# LPC13xx register map
File version: 1
CPU: 
Registers are 32-bit, read-write, reset 0x0 unless marked. A register's access mark holds for its fields unless they carry their own. Offsets are from the block's base; [hi:lo] are bit positions; {n}, {i} and the like mark numbered series; 'fields as' and 'values as' point back to an identical list.

## SYSCON — Product name title=UM10375 Chapter title=LPC13xx System configuration Modification date=4/4/2011 Major revision=2 Minor revision=2
Base 0x40048000
0x00 SYSMEMREMAP reset 0x2 — System memory remap
  [1:0] MAP
    0=BOOT_LOADER_MODE_IN (Boot Loader Mode. Interrupt vectors are re-mapped to Boot ROM.); 1=USER_RAM_MODE_INTER (User RAM Mode. Interrupt vectors are re-mapped to Static RAM.); 2=USER_FLASH_MODE_INT (User Flash Mode. Interrupt vectors are not re-mapped and reside in Flash.)
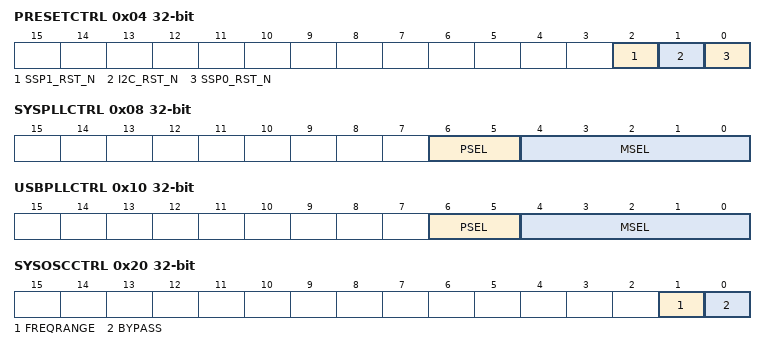
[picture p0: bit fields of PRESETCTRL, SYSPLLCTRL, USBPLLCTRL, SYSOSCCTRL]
0x04 PRESETCTRL — Peripheral reset control
  [2] SSP1_RST_N — SPISP1 reset control
    0=RESET_THE_SPISP1_; 1=DE_ASSERT_SPISP1_RES (De-assert SPISP1 reset.)
  [1] I2C_RST_N — I2C reset control
    0=RESET_I2C_; 1=DE_ASSET_I2C_RESET_
  [0] SSP0_RST_N — SSP0 reset control
    0=RESET_SSP0_; 1=DE_ASSERT_SSP0_RESET
0x08 SYSPLLCTRL — System PLL control
  [6:5] PSEL — Post divider ratio P. The division ratio is 2 x P.
    0=P_EQ_1 (P = 1); 1=P_EQ_2 (P = 2); 2=P_EQ_4 (P = 4); 3=P_EQ_8 (P = 8)
  [4:0] MSEL — Feedback divider value. The division value M is the programmed MSEL value + 1. 00000: Division ratio M = 1 to 11111: Division ratio M = 32.
0x0C SYSPLLSTAT ro — System PLL status
  [0] LOCK — PLL lock status
    0=PLL_NOT_LOCKED; 1=PLL_LOCKED
0x10 USBPLLCTRL — USB PLL control
  fields as SYSPLLCTRL
0x14 USBPLLSTAT ro — USB PLL status
  [0] LOCK — PLL lock status
    0=PLL_NOT_LOCKED; 1=PLL_LOCKED
0x20 SYSOSCCTRL — System oscillator control
  [1] FREQRANGE — Determines frequency range for Low-power oscillator.
    0=1__20_MHZ_FREQUENCY (1 - 20 MHz frequency range.); 1=15__25_MHZ_FREQUENC (15 - 25 MHz frequency range)
  [0] BYPASS — Bypass system oscillator
    0=OSCILLATOR_IS_NOT_BY (Oscillator is not bypassed.); 1=BYPASS_ENABLED_PLL_ (Bypass enabled. PLL input (sys_osc_clk) is fed directly from the XTALIN and XTALOUT pins.)
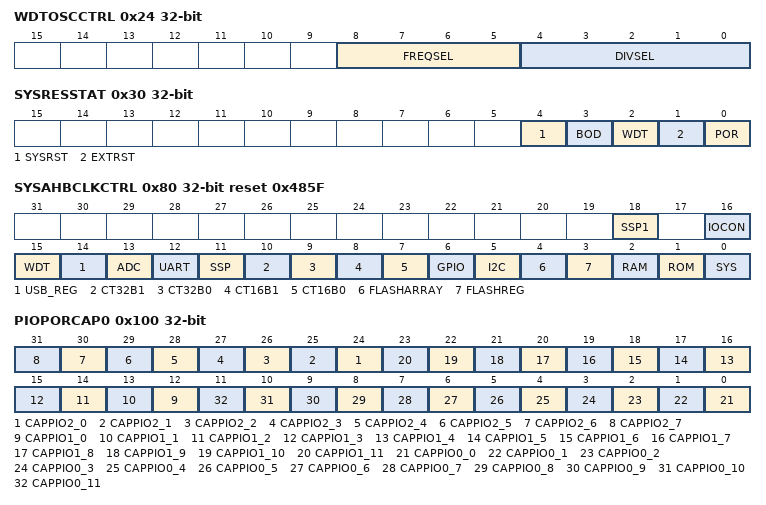
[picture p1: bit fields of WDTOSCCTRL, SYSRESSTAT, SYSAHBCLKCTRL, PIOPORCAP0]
0x24 WDTOSCCTRL — Watchdog oscillator control
  [8:5] FREQSEL — Select watchdog oscillator analog output frequency (Fclkana).
    1=0_5_MHZ; 2=0_8_MHZ; 3=1_1_MHZ; 4=1_4_MHZ; 5=1_6_MHZ; 6=1_8_MHZ; 7=2_0_MHZ; 8=2_2_MHZ; 9=2_4_MHZ; 10=2_6_MHZ; 11=2_7_MHZ; 12=2_9_MHZ; 13=3_1_MHZ; 14=3_2_MHZ; 15=3_4_MHZ
  [4:0] DIVSEL — Select divider for Fclkana. wdt_osc_clk = Fclkana (2 x (1 + DIVSEL)). 00000: 2 x (1 + DIVSEL) = 2 00001: 2 x (1 + DIVSEL) = 4 to 11111: 2 x (1 + DIVSEL) = 64
0x28 IRCCTRL reset 0x80 — IRC control
  [7:0] TRIM — Trim value
0x30 SYSRESSTAT ro — System reset status register
  [4] SYSRST — Status of the software system reset. The ARM software reset has the same effect as the hardware reset using the RESET pin.
    0=NO_SYSTEM_RESET_DETE (No System reset detected); 1=SYSTEM_RESET_DETECTE (System reset detected)
  [3] BOD — Status of the Brown-out detect reset
    0=NO_BOD_RESET_DETECTE (No BOD reset detected); 1=BOD_RESET_DETECTED
  [2] WDT — Status of the Watchdog reset
    0=NO_WDT_RESET_DETECTE (No WDT reset detected); 1=WDT_RESET_DETECTED
  [1] EXTRST — Status of the external RESET pin
    0=NO_RESET_EVENT_DETEC (No RESET event detected); 1=RESET_DETECTED
  [0] POR — POR reset status
    0=NO_POR_DETECTED; 1=POR_DETECTED
0x40 SYSPLLCLKSEL — System PLL clock source select
  [1:0] SEL — System PLL clock source
    0=IRC_OSCILLATOR; 1=SYSTEM_OSCILLATOR
0x44 SYSPLLCLKUEN — System PLL clock source update enable
  [0] ENA — Enable system PLL clock source update
    0=NO_CHANGE; 1=UPDATE_CLOCK_SOURCE
0x48 USBPLLCLKSEL — USB PLL clock source select
  [1:0] SEL — USB PLL clock source
    0=IRC_THE_USB_PLL_CLO (IRC. The USB PLL clock source must be switched to system oscillator for correct USB operation.); 1=SYSTEM_OSCILLATOR
0x4C USBPLLCLKUEN — USB PLL clock source update enable
  [0] ENA — Enable USB PLL clock source update
    0=NO_CHANGE; 1=UPDATE_CLOCK_SOURCE
0x70 MAINCLKSEL — Main clock source select
  [1:0] SEL — Clock source for main clock
    0=IRC_OSCILLATOR; 1=INPUT_CLOCK_TO_SYSTE (Input clock to system PLL); 2=WDT_OSCILLATOR; 3=SYSTEM_PLL_CLOCK_OUT
0x74 MAINCLKUEN — Main clock source update enable
  [0] ENA — Enable main clock source update
    0=NO_CHANGE; 1=UPDATE_CLOCK_SOURCE
0x78 SYSAHBCLKDIV reset 0x1 — System AHB clock divider
  [7:0] DIV — System AHB clock divider values 0: System clock disabled. 1: Divide by 1. to 255: Divide by 255.
0x80 SYSAHBCLKCTRL reset 0x485F — System AHB clock control
  [18] SSP1 — Enables clock for SPISP1.
    0=DISABLE; 1=ENABLE
  [16] IOCON — Enables clock for IO configuration block.
    0=DISABLED; 1=ENABLED
  [15] WDT — Enables clock for WDT.
    0=DISABLED; 1=ENABLED
  [14] USB_REG — Enables clock for USB_REG.
    0=DISABLED; 1=ENABLED
  [13] ADC — Enables clock for ADC.
    0=DISABLED; 1=ENABLED
  [12] UART — Enables clock for UART. Note that the UART pins must be configured in the IOCON block before the UART clock can be enabled.
    0=DISABLED; 1=ENABLED
  [11] SSP — Enables clock for SSP.
    0=DISABLED; 1=ENABLED
  [10] CT32B1 — Enables clock for 32-bit counter/timer 1.
    0=DISABLED; 1=ENABLED
  [9] CT32B0 — Enables clock for 32-bit counter/timer 0.
    0=DISABLED; 1=ENABLED
  [8] CT16B1 — Enables clock for 16-bit counter/timer 1.
    0=DISABLED; 1=ENABLED
  [7] CT16B0 — Enables clock for 16-bit counter/timer 0.
    0=DISABLED; 1=ENABLED
  [6] GPIO — Enables clock for GPIO.
    0=DISABLED; 1=ENABLED
  [5] I2C — Enables clock for I2C.
    0=DISABLED; 1=ENABLED
  [4] FLASHARRAY — Enables clock for flash array access.
    0=DISABLED; 1=ENABLED
  [3] FLASHREG — Enables clock for flash register interface.
    0=DISABLED; 1=ENABLED
  [2] RAM — Enables clock for RAM.
    0=DISABLED; 1=ENABLED
  [1] ROM — Enables clock for ROM.
    0=DISABLED; 1=ENABLED
  [0] SYS — Enables clock for AHB to APB bridge, to the AHB matrix, to the Cortex-M3 FCLK and HCLK, to the SysCon, and to the PMU. This bit is read only.
    1=ENABLED
0x94 SSP0CLKDIV reset 0x1 — SSP clock divder
  [7:0] DIV — SSP_PCLK clock divider values. 0: Disable SSP0_PCLK. 1: Divide by 1. to 255: Divide by 255.
0x98 UARTCLKDIV — UART clock divder
  [7:0] DIV — UART_PCLK clock divider values 0: Disable UART_PCLK. 1: Divide by 1. to 255: Divide by 255.
0x9C SSP1CLKDIV — SPISP1 clock divder
  [7:0] DIV — SSP1_PCLK clock divider values 0: Disable SSP1_PCLK. 1: Divide by 1. to 255: Divide by 255.
0xAC TRACECLKDIV — ARM trace clock divider
  [7:0] DIV — ARM trace clock divider values. 0: Disable TRACE_CLK. 1: Divide by 1. to 255: Divide by 255.
0xB0 SYSTICKCLKDIV — SYSTICK clock divder
  [7:0] DIV — SYSTICK clock divider values. 0: Disable SYSTICK timer clock. 1: Divide by 1. to 255: Divide by 255.
0xC0 USBCLKSEL — USB clock source select
  [1:0] SEL — USB clock source
    0=USB_PLL_OUT; 1=MAIN_CLOCK
0xC4 USBCLKUEN — USB clock source update enable
  [0] ENA — Enable USB clock source update
    0=NO_CHANGE; 1=UPDATE_CLOCK_SOURCE
0xC8 USBCLKDIV reset 0x1 — USB clock source divider
  [7:0] DIV — USB clock divider values. 0: Disable USB clock. 1: Divide by 1. to 255: Divide by 255.
0xD0 WDTCLKSEL — WDT clock source select
  [1:0] SEL — WDT clock source
    0=IRC_OSCILLATOR; 1=MAIN_CLOCK; 2=WATCHDOG_OSCILLATOR
0xD4 WDTCLKUEN — WDT clock source update enable
  [0] ENA — Enable WDT clock source update
    0=NO_CHANGE; 1=UPDATE_CLOCK_SOURCE
0xD8 WDTCLKDIV — WDT clock divider
  [7:0] DIV — WDT clock divider values. 0: Disable WDCLK. 1: Divide by 1. to 255: Divide by 255.
0xE0 CLKOUTCLKSEL — CLKOUT clock source select
  [1:0] SEL — CLKOUT clock source
    0=IRC_OSCILLATOR; 1=SYSTEM_OSCILLATOR; 2=WATCHDOG_OSCILLATOR; 3=MAIN_CLOCK
0xE4 CLKOUTUEN — CLKOUT clock source update enable
  [0] ENA — Enable CLKOUT clock source update
    0=NO_CHANGE; 1=UPDATE_CLOCK_SOURCE
0xE8 CLKOUTDIV — CLKOUT clock divider
  [7:0] DIV — Clock divider values. 0: Disable CLKOUT. 1: Divide by 1. to 255: Divide by 255.
0x100 PIOPORCAP0 ro reset not defined — POR captured PIO status 0
  [n+24] CAPPIO2_{n} (n=0..7) — Raw reset status input PIO2_7 to PIO2_0
  [n+12] CAPPIO1_{n} (n=0..11) — Raw reset status input PIO1_11 to PIO1_0
  [n] CAPPIO0_{n} (n=0..11) — Raw reset status input PIO0_11 to PIO0_0
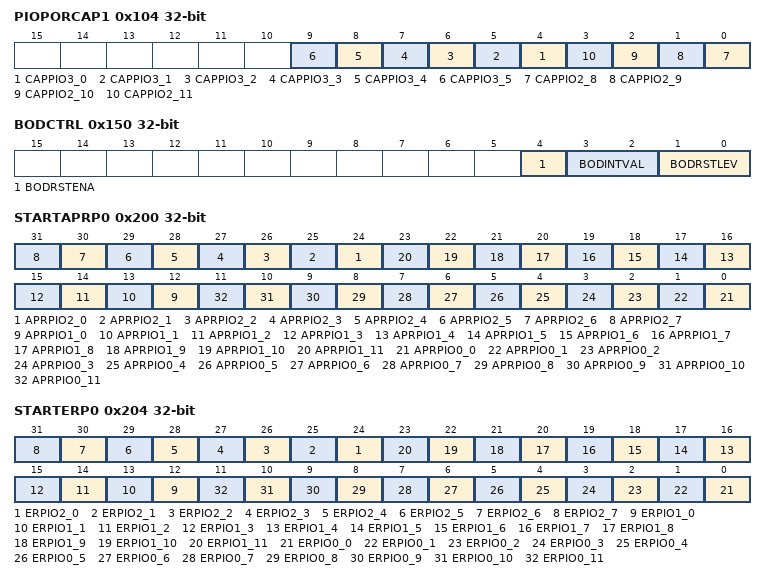
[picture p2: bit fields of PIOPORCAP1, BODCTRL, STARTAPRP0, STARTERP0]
0x104 PIOPORCAP1 ro reset not defined — POR captured PIO status 1
  [n+4] CAPPIO3_{n} (n=0..5) — Raw reset status input PIO3_{n}
  [n-8] CAPPIO2_{n} (n=8..11) — Raw reset status input PIO2_{n}
0x150 BODCTRL — BOD control
  [4] BODRSTENA — BOD reset enable
    0=DISABLE_RESET_FUNCTI (Disable reset function.); 1=ENABLE_RESET_FUNCTIO (Enable reset function.)
  [3:2] BODINTVAL — BOD interrupt level. Trip values x/y refer to the LPC1300/LPC1300L series.
    0=THE_INTERRUPT_ASSERT (The interrupt assertion threshold voltage is 1.69 V/1.65 V; the interrupt de-assertion threshold voltage is 1.84 V/1.8 V.); 1=THE_INTERRUPT_ASSERT (The interrupt assertion threshold voltage is 2.29 V/2.22 V; the interrupt de-assertion threshold voltage is 2.44 V/2.35 V.); 2=THE_INTERRUPT_ASSERT (The interrupt assertion threshold voltage is 2.59 V/ 2.52 V; the interrupt de-assertion threshold voltage is 2.74 V/2.66 V.); 3=THE_INTERRUPT_ASSERT (The interrupt assertion threshold voltage is 2.87 V/2.80 V; the interrupt de-assertion threshold voltage is 2.98 V/2.90 V.)
  [1:0] BODRSTLEV — BOD reset level. Trip values x/y refer to the LPC1300/LPC1300L series.
    0=THE_RESET_ASSERTION_ (The reset assertion threshold voltage is 1.49 V/1.46 V; the reset de-assertion threshold voltage is 1.64 V/1.63 V.); 1=THE_RESET_ASSERTION_ (The reset assertion threshold voltage is -/2.06 V; the reset de-assertion threshold voltage is -/2.15 V.); 2=THE_RESET_ASSERTION_ (The reset assertion threshold voltage is -/2.35 V; the reset de-assertion threshold voltage is -/2.43 V.); 3=THE_RESET_ASSERTION_ (The reset assertion threshold voltage is -/2.63 V; the reset de-assertion threshold voltage is -/2.71 V.)
0x154 SYSTCKCAL reset 0x4 — System tick counter calibration
  [25:0] CAL — System tick timer calibration value
0x200 STARTAPRP0 reset not defined — Start logic edge control register 0; bottom 32 interrupts
  [n+24] APRPIO2_{n} (n=0..7) — Edge select for start logic input PIO2_n (bit 24 = PIO2_0, ..., bit 31 = PIO2_7). 0 = Falling edge. 1 = Rising edge.
  [n+12] APRPIO1_{n} (n=0..11) — Edge select for start logic input PIO1_n (bit 12 = PIO1_0, ..., bit 23 = PIO1_11). 0 = Falling edge. 1 = Rising edge.
  [n] APRPIO0_{n} (n=0..11) — Edge select for start logic input PIO0_n (bit 0 = PIO0_1, ..., bit 11 = PIO0_11). 0 = Falling edge. 1 = Rising edge.
0x204 STARTERP0 reset not defined — Start logic signal enable register 0; bottom 32 interrupts
  [n+24] ERPIO2_{n} (n=0..7) — Enable start signal for start logic input PIO2_n (bit 24 = PIO2_0, ..., bit 31 = PIO2_7). 0 = Disabled. 1 = Enabled.
  [n+12] ERPIO1_{n} (n=0..11) — Enable start signal for start logic input PIO1_n (bit 12 = PIO1_0, ..., bit 23 = PIO1_11). 0 = Disabled. 1 = Enabled.
  [n] ERPIO0_{n} (n=0..11) — Enable start signal for start logic input PIO0_n (bit 0 = PIO0_1, ..., bit 11 = PIO0_11). 0 = Disabled. 1 = Enabled.
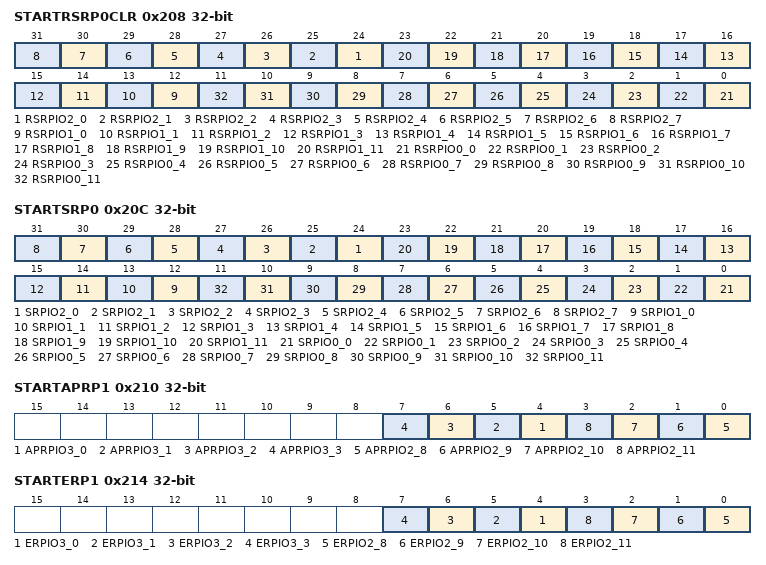
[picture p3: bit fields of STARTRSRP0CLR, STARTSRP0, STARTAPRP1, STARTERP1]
0x208 STARTRSRP0CLR wo reset not defined — Start logic reset register 0; bottom 32 interrupts
  [n+24] RSRPIO2_{n} (n=0..7) — Start signal reset for start logic input PIO2_n (bit 24 = PIO2_0, ..., bit 31 = PIO2_7). 0 = Do nothing. 1 = Write: reset start signal.
  [n+12] RSRPIO1_{n} (n=0..11) — Start signal reset for start logic input PIO1_n (bit 12 = PIO1_0, ..., bit 23 = PIO1_11). 0 = Do nothing. 1 = Write: reset start signal.
  [n] RSRPIO0_{n} (n=0..11) — Start signal reset for start logic input PIO0_n (bit 0 = PIO0_1, ..., bit 11 = PIO0_11). 0 = Do nothing. 1 = Write: reset start signal.
0x20C STARTSRP0 ro reset not defined — Start logic status register 0; bottom 32 interrupts
  [n+24] SRPIO2_{n} (n=0..7) — Start signal status for start logic input PIO2_n (bit 24 = PIO2_0, ..., bit 31 = PIO2_7). 0 = No start signal received. 1 = Start signal pending.
  [n+12] SRPIO1_{n} (n=0..11) — Start signal status for start logic input PIO1_n (bit 12 = PIO1_0, ..., bit 23 = PIO1_11). 0 = No start signal received. 1 = Start signal pending.
  [n] SRPIO0_{n} (n=0..11) — Start signal status for start logic input PIO0_n (bit 0 = PIO0_1, ..., bit 11 = PIO0_11). 0 = No start signal received. 1 = Start signal pending.
0x210 STARTAPRP1 reset not defined — Start logic edge control register 1; top 8 interrupts
  [n+4] APRPIO3_{n} (n=0..3) — Edge select for start logic input PIO3_n (bit 4 = PIO3_0, ..., bit 7 = PIO3_3). 0 = Falling edge. 1 = Rising edge.
  [n-8] APRPIO2_{n} (n=8..11) — Edge select for start logic input PIO2_n (bit 0 = PIO2_8, ..., bit 3 = PIO2_11). 0 = Falling edge. 1 = Rising edge.
0x214 STARTERP1 reset not defined — Start logic signal enable register 1; top 8 interrupts
  [n+4] ERPIO3_{n} (n=0..3) — Enable start signal for start logic input PIO3_n (bit 4 = PIO3_0, ..., bit 7 = PIO3_3). 0 = Disabled. 1 = Enabled.
  [n-8] ERPIO2_{n} (n=8..11) — Enable start signal for start logic input PIO2_n (bit 0 = PIO2_8, ..., bit 3 = PIO2_11). 0 = Disabled. 1 = Enabled.
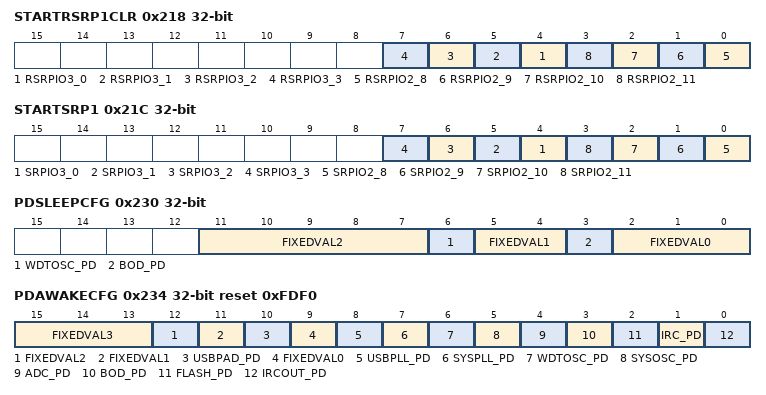
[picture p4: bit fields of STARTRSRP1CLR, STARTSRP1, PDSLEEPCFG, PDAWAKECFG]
0x218 STARTRSRP1CLR wo reset not defined — Start logic reset register 1; top 8 interrupts
  [n+4] RSRPIO3_{n} (n=0..3) — Start signal reset for start logic input PIO3_n (bit 4 = PIO3_0, ..., bit 7 = PIO3_3). 0 = Do nothing.. 1 = Write: reset start signal.
  [n-8] RSRPIO2_{n} (n=8..11) — Start signal reset for start logic input PIO2_n (bit 0 = PIO2_8, ..., bit 3 = PIO2_11). 0 = Do nothing.. 1 = Write: reset start signal.
0x21C STARTSRP1 ro reset not defined — Start logic status register 1; top 8 interrupts
  [n+4] SRPIO3_{n} (n=0..3) — Start signal status for start logic input PIO3_n (bit 4 = PIO3_0, ..., bit 7 = PIO3_3). 0 = No start signal received. 1 = Start signal pending.
  [n-8] SRPIO2_{n} (n=8..11) — Start signal status for start logic input PIO2_n (bit 0 = PIO2_8, ..., bit 3 = PIO2_11). 0 = No start signal received. 1 = Start signal pending.
0x230 PDSLEEPCFG — Power-down states in Deep-sleep mode
  [11:7] FIXEDVAL2 — Reserved. Always write these bits as 11111.
  [6] WDTOSC_PD — Watchdog oscillator power control in Deep-sleep mode, see Table 49.
    0=POWERED; 1=POWERED_DOWN
  [5:4] FIXEDVAL1 — Reserved. Always write these bits as 11.
  [3] BOD_PD — BOD power-down control in Deep-sleep mode, see Table 49.
    0=POWERED; 1=POWERED_DOWN
  [2:0] FIXEDVAL0 — Reserved. Always write these bits as 111.
0x234 PDAWAKECFG reset 0xFDF0 — Power-down states after wake-up from Deep-sleep mode
  [15:13] FIXEDVAL3 — Reserved. Always write these bits as 111.
  [12] FIXEDVAL2 — Reserved. Always write this bit as 0.
  [11] FIXEDVAL1 — Reserved. Always write this bit as 1.
  [10] USBPAD_PD — USB pad wake-up configuration
    0=USB_PHY_POWERED; 1=USB_PHY_POWERED_DOWN
  [9] FIXEDVAL0 — Reserved. Always write this bit as 0.
  [8] USBPLL_PD — USB PLL wake-up configuration
    0=POWERED; 1=POWERED_DOWN
  [7] SYSPLL_PD — System PLL wake-up configuration
    0=POWERED; 1=POWERED_DOWN
  [6] WDTOSC_PD — Watchdog oscillator wake-up configuration
    0=POWERED; 1=POWERED_DOWN
  [5] SYSOSC_PD — System oscillator wake-up configuration
    0=POWERED; 1=POWERED_DOWN
  [4] ADC_PD — ADC wake-up configuration
    0=POWERED; 1=POWERED_DOWN
  [3] BOD_PD — BOD wake-up configuration
    0=POWERED; 1=POWERED_DOWN
  [2] FLASH_PD — Flash wake-up configuration
    0=POWERED; 1=POWERED_DOWN
  [1] IRC_PD — IRC oscillator power-down wake-up configuration
    0=POWERED; 1=POWERED_DOWN
  [0] IRCOUT_PD — IRC oscillator output wake-up configuration
    0=POWERED; 1=POWERED_DOWN
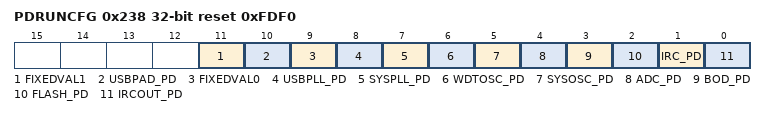
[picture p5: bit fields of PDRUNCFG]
0x238 PDRUNCFG reset 0xFDF0 — Power-down configuration register
  [11] FIXEDVAL1 — Reserved. Always write this bit as 1.
  [10] USBPAD_PD — USB pad power-down configuration
    0=USB_PHY_POWERED; 1=USB_PHY_POWERED_DOWN (USB PHY powered down (suspend mode))
  [9] FIXEDVAL0 — Reserved. Always write this bit as 0.
  [8] USBPLL_PD — USB PLL power-down
    0=POWERED; 1=POWERED_DOWN
  [7] SYSPLL_PD — System PLL power-down
    0=POWERED; 1=POWERED_DOWN
  [6] WDTOSC_PD — Watchdog oscillator power-down
    0=POWERED; 1=POWERED_DOWN
  [5] SYSOSC_PD — System oscillator power-down[1]
    0=POWERED; 1=POWERED_DOWN
  [4] ADC_PD — ADC power-down
    0=POWERED; 1=POWERED_DOWN
  [3] BOD_PD — BOD power-down
    0=POWERED; 1=POWERED_DOWN
  [2] FLASH_PD — Flash power-down
    0=POWERED; 1=POWERED_DOWN
  [1] IRC_PD — IRC oscillator power-down
    0=POWERED; 1=POWERED_DOWN
  [0] IRCOUT_PD — IRC oscillator output power-down
    0=POWERED; 1=POWERED_DOWN
0x3F4 DEVICE_ID ro reset not defined
  [31:0] DEVICEID — Device ID for LPC13xx parts: 0x2C42 502B = LPC1311FHN33 0x2C40 102B = LPC1313FHN33 0x2C40 102B = LPC1313FBD48 0x3D01 402B = LPC1342FHN33 0x3D00 002B = LPC1343FHN33 0x3D00 002B = LPC1343FBD48 0x1816 902B = LPC1311FHN33/01 0x1830 102B = LPC1313FHN33/01 0x1830 102B = LPC1313FBD48/01
